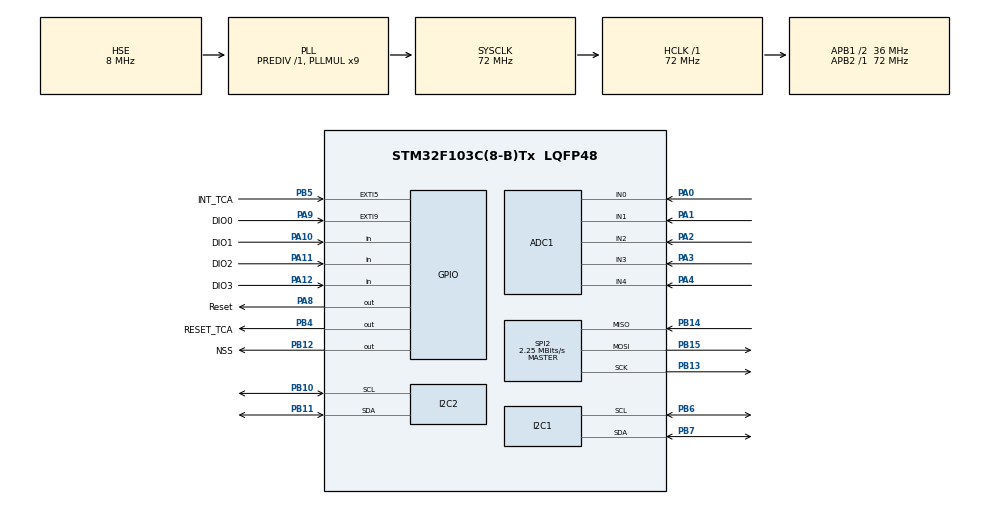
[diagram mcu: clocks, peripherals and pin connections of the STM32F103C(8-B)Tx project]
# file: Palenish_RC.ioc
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ADC1.Channel-0\#ChannelRegularConversion=ADC_CHANNEL_0
ADC1.Channel-1\#ChannelRegularConversion=ADC_CHANNEL_1
ADC1.Channel-2\#ChannelRegularConversion=ADC_CHANNEL_2
ADC1.Channel-3\#ChannelRegularConversion=ADC_CHANNEL_3
ADC1.Channel-4\#ChannelRegularConversion=ADC_CHANNEL_4
ADC1.NbrOfConversion=5
ADC1.NbrOfConversionFlag=1
ADC1.Rank-0\#ChannelRegularConversion=1
ADC1.Rank-1\#ChannelRegularConversion=2
ADC1.Rank-2\#ChannelRegularConversion=3
ADC1.Rank-3\#ChannelRegularConversion=4
ADC1.Rank-4\#ChannelRegularConversion=5
ADC1.SamplingTime-0\#ChannelRegularConversion=ADC_SAMPLETIME_239CYCLES_5
ADC1.SamplingTime-1\#ChannelRegularConversion=ADC_SAMPLETIME_239CYCLES_5
ADC1.SamplingTime-2\#ChannelRegularConversion=ADC_SAMPLETIME_239CYCLES_5
ADC1.SamplingTime-3\#ChannelRegularConversion=ADC_SAMPLETIME_239CYCLES_5
ADC1.SamplingTime-4\#ChannelRegularConversion=ADC_SAMPLETIME_239CYCLES_5
ADC1.master=1
Dma.ADC1.0.Direction=DMA_PERIPH_TO_MEMORY
Dma.ADC1.0.Instance=DMA1_Channel1
Dma.ADC1.0.MemDataAlignment=DMA_MDATAALIGN_WORD
Dma.ADC1.0.MemInc=DMA_MINC_ENABLE
Dma.ADC1.0.Mode=DMA_NORMAL
Dma.ADC1.0.PeriphDataAlignment=DMA_PDATAALIGN_HALFWORD
Dma.ADC1.0.PeriphInc=DMA_PINC_DISABLE
Dma.ADC1.0.Priority=DMA_PRIORITY_LOW
Dma.Request0=ADC1
I2C2.NoStretchMode=I2C_NOSTRETCH_ENABLE
Mcu.Family=STM32F1
Mcu.Name=STM32F103C(8-B)Tx
Mcu.Package=LQFP48
NVIC.DMA1_Channel1_IRQn=true\:1\:0\:true\:false\:true\:false\:true\:true
NVIC.EXTI9_5_IRQn=true\:3\:0\:true\:false\:true\:true\:true\:true
NVIC.FLASH_IRQn=true\:0\:0\:false\:false\:true\:true\:true\:true
NVIC.I2C1_ER_IRQn=true\:15\:0\:true\:false\:true\:true\:true\:true
NVIC.I2C1_EV_IRQn=true\:15\:0\:true\:false\:true\:true\:true\:true
NVIC.I2C2_EV_IRQn=true\:2\:0\:true\:false\:true\:true\:true\:true
NVIC.PriorityGroup=NVIC_PRIORITYGROUP_4
NVIC.RCC_IRQn=true\:0\:0\:true\:false\:true\:true\:false\:true
NVIC.RTC_IRQn=true\:5\:0\:true\:false\:true\:true\:true\:true
NVIC.SPI2_IRQn=true\:2\:0\:true\:false\:true\:true\:true\:true
PA0-WKUP.Signal=ADCx_IN0
PA1.Signal=ADCx_IN1
PA10.GPIO_Label=DIO1
PA10.GPIO_PuPd=GPIO_PULLDOWN
PA10.Signal=GPIO_Input
PA11.GPIO_Label=DIO2
PA11.GPIO_PuPd=GPIO_PULLDOWN
PA11.Signal=GPIO_Input
PA12.GPIO_Label=DIO3
PA12.GPIO_PuPd=GPIO_PULLDOWN
PA12.Signal=GPIO_Input
PA13.Mode=Serial_Wire
PA13.Signal=SYS_JTMS-SWDIO
PA14.Mode=Serial_Wire
PA14.Signal=SYS_JTCK-SWCLK
PA2.Signal=ADCx_IN2
PA3.Signal=ADCx_IN3
PA4.Signal=ADCx_IN4
PA8.GPIO_Label=Reset
PA8.GPIO_PuPd=GPIO_PULLUP
PA8.Signal=GPIO_Output
PA9.GPIO_Label=DIO0
PA9.GPIO_PuPd=GPIO_PULLDOWN
PA9.Signal=GPXTI9
PB10.Mode=I2C
PB10.Signal=I2C2_SCL
PB11.Mode=I2C
PB11.Signal=I2C2_SDA
PB12.GPIO_Label=NSS
PB12.GPIO_PuPd=GPIO_PULLUP
PB12.Signal=GPIO_Output
PB13.Mode=Full_Duplex_Master
PB13.Signal=SPI2_SCK
PB14.Mode=Full_Duplex_Master
PB14.Signal=SPI2_MISO
PB15.Mode=Full_Duplex_Master
PB15.Signal=SPI2_MOSI
PB4.GPIO_Label=RESET_TCA
PB4.GPIO_PuPd=GPIO_PULLUP
PB4.PinState=GPIO_PIN_SET
PB4.Signal=GPIO_Output
PB5.GPIO_Label=INT_TCA
PB5.GPIO_ModeDefaultEXTI=GPIO_MODE_IT_FALLING
PB5.GPIO_PuPd=GPIO_PULLDOWN
PB5.Signal=GPXTI5
PB6.Mode=I2C
PB6.Signal=I2C1_SCL
PB7.Mode=I2C
PB7.Signal=I2C1_SDA
PC14-OSC32_IN.Mode=LSE-External-Oscillator
PC14-OSC32_IN.Signal=RCC_OSC32_IN
PC15-OSC32_OUT.Mode=LSE-External-Oscillator
PC15-OSC32_OUT.Signal=RCC_OSC32_OUT
PD0-OSC_IN.Mode=HSE-External-Oscillator
PD0-OSC_IN.Signal=RCC_OSC_IN
PD1-OSC_OUT.Mode=HSE-External-Oscillator
PD1-OSC_OUT.Signal=RCC_OSC_OUT
ProjectManager.HeapSize=0x200
ProjectManager.StackSize=0x400
ProjectManager.TargetToolchain=STM32CubeIDE
RCC.ADCPresc=RCC_ADCPCLK2_DIV8
RCC.AHBFreq_Value=72000000
RCC.APB1CLKDivider=RCC_HCLK_DIV2
RCC.APB1Freq_Value=36000000
RCC.APB1TimFreq_Value=72000000
RCC.APB2Freq_Value=72000000
RCC.APB2TimFreq_Value=72000000
RCC.HCLKFreq_Value=72000000
RCC.PLLMUL=RCC_PLL_MUL9
RCC.PLLSourceVirtual=RCC_PLLSOURCE_HSE
RCC.SYSCLKFreq_VALUE=72000000
RCC.SYSCLKSource=RCC_SYSCLKSOURCE_PLLCLK
RCC.USBFreq_Value=72000000
RTC.AutoPrediv=RTC_AUTO_1_SECOND
RTC.Format=RTC_FORMAT_BCD
SH.ADCx_IN0.0=ADC1_IN0,IN0
SH.ADCx_IN1.0=ADC1_IN1,IN1
SH.ADCx_IN2.0=ADC1_IN2,IN2
SH.ADCx_IN3.0=ADC1_IN3,IN3
SH.ADCx_IN4.0=ADC1_IN4,IN4
SPI2.BaudRatePrescaler=SPI_BAUDRATEPRESCALER_16
SPI2.CalculateBaudRate=2.25 MBits/s
SPI2.Direction=SPI_DIRECTION_2LINES
SPI2.Mode=SPI_MODE_MASTER
SPI2.VirtualType=VM_MASTER
VP_RTC_No_RTC_Output.Mode=RTC_OUT_NO
VP_RTC_VS_RTC_Activate.Mode=RTC_Enabled
board=custom

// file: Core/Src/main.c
/* USER CODE BEGIN Header */
/**
  ******************************************************************************
  * @file           : main.c
  * @brief          : Main program body
  ******************************************************************************
  * @attention
  *
  * Copyright (c) 2025 STMicroelectronics.
  * All rights reserved.
  *
  * This software is licensed under terms that can be found in the LICENSE file
  * in the root directory of this software component.
  * If no LICENSE file comes with this software, it is provided AS-IS.
  *
  ******************************************************************************
  */
/* USER CODE END Header */
#include "main.h"

/* USER CODE BEGIN Includes */
#include "ProgMem.h"
/* USER CODE END Includes */

ADC_HandleTypeDef hadc1;
DMA_HandleTypeDef hdma_adc1;

I2C_HandleTypeDef hi2c1;
I2C_HandleTypeDef hi2c2;

RTC_HandleTypeDef hrtc;

SPI_HandleTypeDef hspi2;

void SystemClock_Config(void);
static void MX_GPIO_Init(void);
static void MX_DMA_Init(void);
static void MX_ADC1_Init(void);
static void MX_I2C1_Init(void);
static void MX_I2C2_Init(void);
static void MX_RTC_Init(void);
static void MX_SPI2_Init(void);

int main(void)
{

  /* MCU Configuration--------------------------------------------------------*/

  /* Reset of all peripherals, Initializes the Flash interface and the Systick. */
  HAL_Init();

  /* Configure the system clock */
  SystemClock_Config();

  /* Initialize all configured peripherals */
  MX_GPIO_Init();
  MX_DMA_Init();
  MX_ADC1_Init();
  MX_I2C1_Init();
  MX_I2C2_Init();
  MX_RTC_Init();
  MX_SPI2_Init();
  /* USER CODE BEGIN 2 */

  StartInitCalValues(&CalibrValues);

  MatrixConfig8418(&hi2c1);
  disp1color_Init();
  LoRaMenuInit();

  MenuHandl(&MenuStructOld);

  /* USER CODE END 2 */

  /* Infinite loop */
  while (1)
  {

  }
}

void SystemClock_Config(void)
{
  RCC_OscInitTypeDef RCC_OscInitStruct = {0};
  RCC_ClkInitTypeDef RCC_ClkInitStruct = {0};
  RCC_PeriphCLKInitTypeDef PeriphClkInit = {0};

  /** Initializes the RCC Oscillators according to the specified parameters
  * in the RCC_OscInitTypeDef structure.
  */
  RCC_OscInitStruct.OscillatorType = RCC_OSCILLATORTYPE_LSI|RCC_OSCILLATORTYPE_HSE;
  RCC_OscInitStruct.HSEState = RCC_HSE_ON;
  RCC_OscInitStruct.HSEPredivValue = RCC_HSE_PREDIV_DIV1;
  RCC_OscInitStruct.HSIState = RCC_HSI_ON;
  RCC_OscInitStruct.LSIState = RCC_LSI_ON;
  RCC_OscInitStruct.PLL.PLLState = RCC_PLL_ON;
  RCC_OscInitStruct.PLL.PLLSource = RCC_PLLSOURCE_HSE;
  RCC_OscInitStruct.PLL.PLLMUL = RCC_PLL_MUL9;
  if (HAL_RCC_OscConfig(&RCC_OscInitStruct) != HAL_OK)
  {
    Error_Handler();
  }

  /** Initializes the CPU, AHB and APB buses clocks
  */
  RCC_ClkInitStruct.ClockType = RCC_CLOCKTYPE_HCLK|RCC_CLOCKTYPE_SYSCLK
                              |RCC_CLOCKTYPE_PCLK1|RCC_CLOCKTYPE_PCLK2;
  RCC_ClkInitStruct.SYSCLKSource = RCC_SYSCLKSOURCE_PLLCLK;
  RCC_ClkInitStruct.AHBCLKDivider = RCC_SYSCLK_DIV1;
  RCC_ClkInitStruct.APB1CLKDivider = RCC_HCLK_DIV2;
  RCC_ClkInitStruct.APB2CLKDivider = RCC_HCLK_DIV1;

  if (HAL_RCC_ClockConfig(&RCC_ClkInitStruct, FLASH_LATENCY_2) != HAL_OK)
  {
    Error_Handler();
  }
  PeriphClkInit.PeriphClockSelection = RCC_PERIPHCLK_RTC|RCC_PERIPHCLK_ADC;
  PeriphClkInit.RTCClockSelection = RCC_RTCCLKSOURCE_LSI;
  PeriphClkInit.AdcClockSelection = RCC_ADCPCLK2_DIV8;
  if (HAL_RCCEx_PeriphCLKConfig(&PeriphClkInit) != HAL_OK)
  {
    Error_Handler();
  }
}

static void MX_ADC1_Init(void)
{

  ADC_ChannelConfTypeDef sConfig = {0};

  /** Common config
  */
  hadc1.Instance = ADC1;
  hadc1.Init.ScanConvMode = ADC_SCAN_ENABLE;
  hadc1.Init.ContinuousConvMode = DISABLE;
  hadc1.Init.DiscontinuousConvMode = DISABLE;
  hadc1.Init.ExternalTrigConv = ADC_SOFTWARE_START;
  hadc1.Init.DataAlign = ADC_DATAALIGN_RIGHT;
  hadc1.Init.NbrOfConversion = 5;
  if (HAL_ADC_Init(&hadc1) != HAL_OK)
  {
    Error_Handler();
  }

  /** Configure Regular Channel
  */
  sConfig.Channel = ADC_CHANNEL_0;
  sConfig.Rank = ADC_REGULAR_RANK_1;
  sConfig.SamplingTime = ADC_SAMPLETIME_239CYCLES_5;
  if (HAL_ADC_ConfigChannel(&hadc1, &sConfig) != HAL_OK)
  {
    Error_Handler();
  }

  /** Configure Regular Channel
  */
  sConfig.Channel = ADC_CHANNEL_1;
  sConfig.Rank = ADC_REGULAR_RANK_2;
  if (HAL_ADC_ConfigChannel(&hadc1, &sConfig) != HAL_OK)
  {
    Error_Handler();
  }

  /** Configure Regular Channel
  */
  sConfig.Channel = ADC_CHANNEL_2;
  sConfig.Rank = ADC_REGULAR_RANK_3;
  if (HAL_ADC_ConfigChannel(&hadc1, &sConfig) != HAL_OK)
  {
    Error_Handler();
  }

  /** Configure Regular Channel
  */
  sConfig.Channel = ADC_CHANNEL_3;
  sConfig.Rank = ADC_REGULAR_RANK_4;
  if (HAL_ADC_ConfigChannel(&hadc1, &sConfig) != HAL_OK)
  {
    Error_Handler();
  }

  /** Configure Regular Channel
  */
  sConfig.Channel = ADC_CHANNEL_4;
  sConfig.Rank = ADC_REGULAR_RANK_5;
  if (HAL_ADC_ConfigChannel(&hadc1, &sConfig) != HAL_OK)
  {
    Error_Handler();
  }

}

static void MX_I2C1_Init(void)
{

  hi2c1.Instance = I2C1;
  hi2c1.Init.ClockSpeed = 100000;
  hi2c1.Init.DutyCycle = I2C_DUTYCYCLE_2;
  hi2c1.Init.OwnAddress1 = 0;
  hi2c1.Init.AddressingMode = I2C_ADDRESSINGMODE_7BIT;
  hi2c1.Init.DualAddressMode = I2C_DUALADDRESS_DISABLE;
  hi2c1.Init.OwnAddress2 = 0;
  hi2c1.Init.GeneralCallMode = I2C_GENERALCALL_DISABLE;
  hi2c1.Init.NoStretchMode = I2C_NOSTRETCH_DISABLE;
  if (HAL_I2C_Init(&hi2c1) != HAL_OK)
  {
    Error_Handler();
  }

}

static void MX_I2C2_Init(void)
{

  hi2c2.Instance = I2C2;
  hi2c2.Init.ClockSpeed = 100000;
  hi2c2.Init.DutyCycle = I2C_DUTYCYCLE_2;
  hi2c2.Init.OwnAddress1 = 0;
  hi2c2.Init.AddressingMode = I2C_ADDRESSINGMODE_7BIT;
  hi2c2.Init.DualAddressMode = I2C_DUALADDRESS_DISABLE;
  hi2c2.Init.OwnAddress2 = 0;
  hi2c2.Init.GeneralCallMode = I2C_GENERALCALL_DISABLE;
  hi2c2.Init.NoStretchMode = I2C_NOSTRETCH_ENABLE;
  if (HAL_I2C_Init(&hi2c2) != HAL_OK)
  {
    Error_Handler();
  }

}

static void MX_RTC_Init(void)
{

  RTC_TimeTypeDef sTime = {0};
  RTC_DateTypeDef DateToUpdate = {0};

  /** Initialize RTC Only
  */
  hrtc.Instance = RTC;
  hrtc.Init.AsynchPrediv = RTC_AUTO_1_SECOND;
  hrtc.Init.OutPut = RTC_OUTPUTSOURCE_NONE;
  if (HAL_RTC_Init(&hrtc) != HAL_OK)
  {
    Error_Handler();
  }

  /** Initialize RTC and set the Time and Date
  */
  sTime.Hours = 0x0;
  sTime.Minutes = 0x0;
  sTime.Seconds = 0x0;

  if (HAL_RTC_SetTime(&hrtc, &sTime, RTC_FORMAT_BCD) != HAL_OK)
  {
    Error_Handler();
  }
  DateToUpdate.WeekDay = RTC_WEEKDAY_MONDAY;
  DateToUpdate.Month = RTC_MONTH_JANUARY;
  DateToUpdate.Date = 0x1;
  DateToUpdate.Year = 0x0;

  if (HAL_RTC_SetDate(&hrtc, &DateToUpdate, RTC_FORMAT_BCD) != HAL_OK)
  {
    Error_Handler();
  }
  /* USER CODE BEGIN RTC_Init 2 */
  SET_BIT(hrtc.Instance->CRH, RTC_CRH_SECIE);
  /* USER CODE END RTC_Init 2 */

}

static void MX_SPI2_Init(void)
{

  /* SPI2 parameter configuration*/
  hspi2.Instance = SPI2;
  hspi2.Init.Mode = SPI_MODE_MASTER;
  hspi2.Init.Direction = SPI_DIRECTION_2LINES;
  hspi2.Init.DataSize = SPI_DATASIZE_8BIT;
  hspi2.Init.CLKPolarity = SPI_POLARITY_LOW;
  hspi2.Init.CLKPhase = SPI_PHASE_1EDGE;
  hspi2.Init.NSS = SPI_NSS_SOFT;
  hspi2.Init.BaudRatePrescaler = SPI_BAUDRATEPRESCALER_16;
  hspi2.Init.FirstBit = SPI_FIRSTBIT_MSB;
  hspi2.Init.TIMode = SPI_TIMODE_DISABLE;
  hspi2.Init.CRCCalculation = SPI_CRCCALCULATION_DISABLE;
  hspi2.Init.CRCPolynomial = 10;
  if (HAL_SPI_Init(&hspi2) != HAL_OK)
  {
    Error_Handler();
  }

}

static void MX_DMA_Init(void)
{

  /* DMA controller clock enable */
  __HAL_RCC_DMA1_CLK_ENABLE();

  /* DMA interrupt init */
  /* DMA1_Channel1_IRQn interrupt configuration */
  HAL_NVIC_SetPriority(DMA1_Channel1_IRQn, 1, 0);
  HAL_NVIC_EnableIRQ(DMA1_Channel1_IRQn);

}

static void MX_GPIO_Init(void)
{
  GPIO_InitTypeDef GPIO_InitStruct = {0};

  /* GPIO Ports Clock Enable */
  __HAL_RCC_GPIOC_CLK_ENABLE();
  __HAL_RCC_GPIOD_CLK_ENABLE();
  __HAL_RCC_GPIOA_CLK_ENABLE();
  __HAL_RCC_GPIOB_CLK_ENABLE();

  /*Configure GPIO pin Output Level */
  HAL_GPIO_WritePin(NSS_GPIO_Port, NSS_Pin, GPIO_PIN_RESET);

  /*Configure GPIO pin Output Level */
  HAL_GPIO_WritePin(Reset_GPIO_Port, Reset_Pin, GPIO_PIN_RESET);

  /*Configure GPIO pin Output Level */
  HAL_GPIO_WritePin(RESET_TCA_GPIO_Port, RESET_TCA_Pin, GPIO_PIN_SET);

  /*Configure GPIO pins : NSS_Pin RESET_TCA_Pin */
  GPIO_InitStruct.Pin = NSS_Pin|RESET_TCA_Pin;
  GPIO_InitStruct.Mode = GPIO_MODE_OUTPUT_PP;
  GPIO_InitStruct.Pull = GPIO_PULLUP;
  GPIO_InitStruct.Speed = GPIO_SPEED_FREQ_LOW;
  HAL_GPIO_Init(GPIOB, &GPIO_InitStruct);

  /*Configure GPIO pin : Reset_Pin */
  GPIO_InitStruct.Pin = Reset_Pin;
  GPIO_InitStruct.Mode = GPIO_MODE_OUTPUT_PP;
  GPIO_InitStruct.Pull = GPIO_PULLUP;
  GPIO_InitStruct.Speed = GPIO_SPEED_FREQ_LOW;
  HAL_GPIO_Init(Reset_GPIO_Port, &GPIO_InitStruct);

  /*Configure GPIO pin : DIO0_Pin */
  GPIO_InitStruct.Pin = DIO0_Pin;
  GPIO_InitStruct.Mode = GPIO_MODE_IT_RISING;
  GPIO_InitStruct.Pull = GPIO_PULLDOWN;
  HAL_GPIO_Init(DIO0_GPIO_Port, &GPIO_InitStruct);

  /*Configure GPIO pins : DIO1_Pin DIO2_Pin DIO3_Pin */
  GPIO_InitStruct.Pin = DIO1_Pin|DIO2_Pin|DIO3_Pin;
  GPIO_InitStruct.Mode = GPIO_MODE_INPUT;
  GPIO_InitStruct.Pull = GPIO_PULLDOWN;
  HAL_GPIO_Init(GPIOA, &GPIO_InitStruct);

  /*Configure GPIO pin : INT_TCA_Pin */
  GPIO_InitStruct.Pin = INT_TCA_Pin;
  GPIO_InitStruct.Mode = GPIO_MODE_IT_FALLING;
  GPIO_InitStruct.Pull = GPIO_PULLDOWN;
  HAL_GPIO_Init(INT_TCA_GPIO_Port, &GPIO_InitStruct);

  /* EXTI interrupt init*/
  HAL_NVIC_SetPriority(EXTI9_5_IRQn, 3, 0);
  HAL_NVIC_EnableIRQ(EXTI9_5_IRQn);

}

void Error_Handler(void)
{
  __disable_irq();
  while (1)
  {
  }
}
